VERSION "1"

NS_ :

BS_:

BU_: BMS ECU

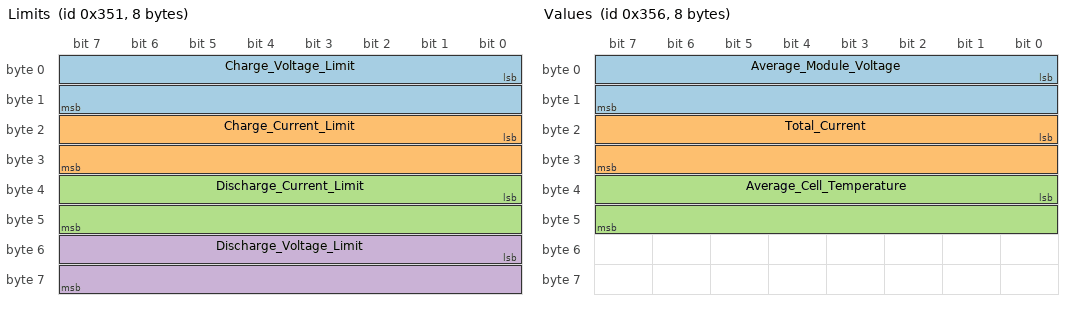
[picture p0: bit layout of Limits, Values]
BO_ 849 Limits: 8 BMS
 SG_ Charge_Voltage_Limit : 0|16@1+ (0.1,0) [0|65.535] "V"  ECU
 SG_ Charge_Current_Limit  : 16|16@1- (0.1,0) [-3276.8|3276.7] "A"  ECU
 SG_ Discharge_Current_Limit  : 32|16@1- (0.1,0) [-3276.8|3276.7] "A"  ECU
 SG_ Discharge_Voltage_Limit : 48|16@1+ (0.1,0) [0|65.535] "V"  ECU

BO_ 853 States: 8 BMS
 SG_ SOC : 0|16@1+ (1,0) [0|100] "%"  ECU
 SG_ SOH : 16|16@1+ (1,0) [0|100] "%"  ECU

BO_ 854 Values: 8 BMS
 SG_ Average_Module_Voltage : 0|16@1+ (0.01,0) [0|655.35] "V"  ECU
 SG_ Total_Current : 16|16@1- (0.1,0) [-3276.8|3276.7] "A"  ECU
 SG_ Average_Cell_Temperature : 32|16@1- (0.1,0) [-3276.8|3276.7] "°C"  ECU

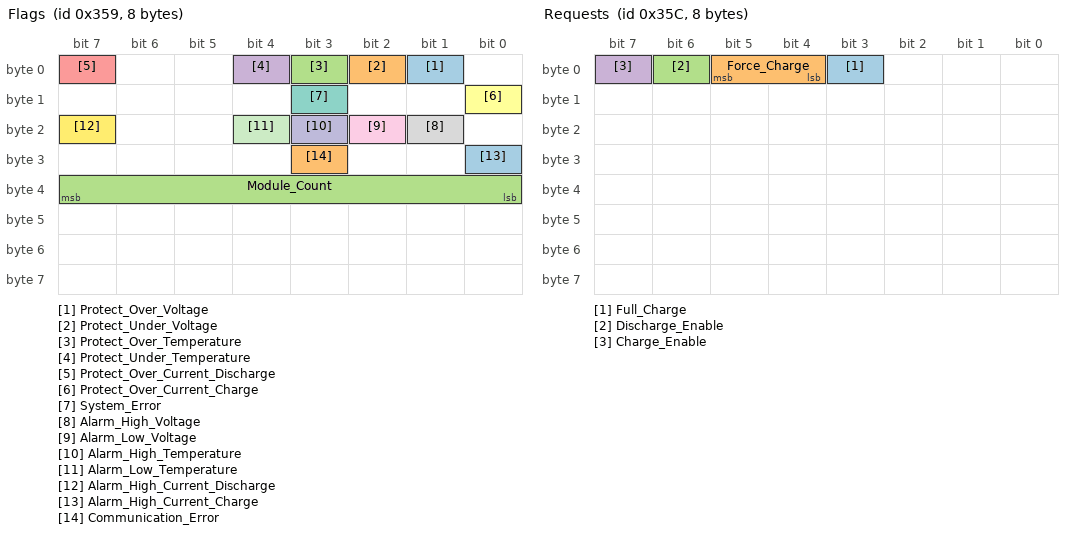
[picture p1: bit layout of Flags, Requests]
BO_ 857 Flags: 8 BMS
 SG_ Protect_Over_Voltage : 1|1@1+ (1,0) [0|1] ""  ECU
 SG_ Protect_Under_Voltage : 2|1@1+ (1,0) [0|1] ""  ECU
 SG_ Protect_Over_Temperature : 3|1@1+ (1,0) [0|1] ""  ECU
 SG_ Protect_Under_Temperature : 4|1@1+ (1,0) [0|1] ""  ECU
 SG_ Protect_Over_Current_Discharge : 7|1@1+ (1,0) [0|1] ""  ECU
 SG_ Protect_Over_Current_Charge : 8|1@1+ (1,0) [0|1] ""  ECU
 SG_ System_Error : 11|1@1+ (1,0) [0|1] ""  ECU
 SG_ Alarm_High_Voltage : 17|1@1+ (1,0) [0|1] ""  ECU
 SG_ Alarm_Low_Voltage : 18|1@1+ (1,0) [0|1] ""  ECU
 SG_ Alarm_High_Temperature : 19|1@1+ (1,0) [0|1] ""  ECU
 SG_ Alarm_Low_Temperature : 20|1@1+ (1,0) [0|1] ""  ECU
 SG_ Alarm_High_Current_Discharge : 23|1@1+ (1,0) [0|1] ""  ECU
 SG_ Alarm_High_Current_Charge : 24|1@1+ (1,0) [0|1] ""  ECU
 SG_ Communication_Error : 27|1@1+ (1,0) [0|1] ""  ECU
 SG_ Module_Count : 32|8@1+ (1,0) [0|65535] ""  ECU

BO_ 860 Requests: 8 BMS
 SG_ Full_Charge : 3|1@1+ (1,0) [0|1] ""  ECU
 SG_ Force_Charge : 4|2@1+ (1,0) [0|1] ""  ECU
 SG_ Discharge_Enable : 6|1@1+ (1,0) [0|1] ""  ECU
 SG_ Charge_Enable : 7|1@1+ (1,0) [0|1] ""  ECU

BO_ 862 Brand: 4 BMS
 SG_ Brand : 0|32@1+ (1,0) [0|128000] ""  ECU

BO_ 863 Firmware: 8 BMS
 SG_ Unknown : 0|64@1+ (1,0) [0|256000] ""  ECU

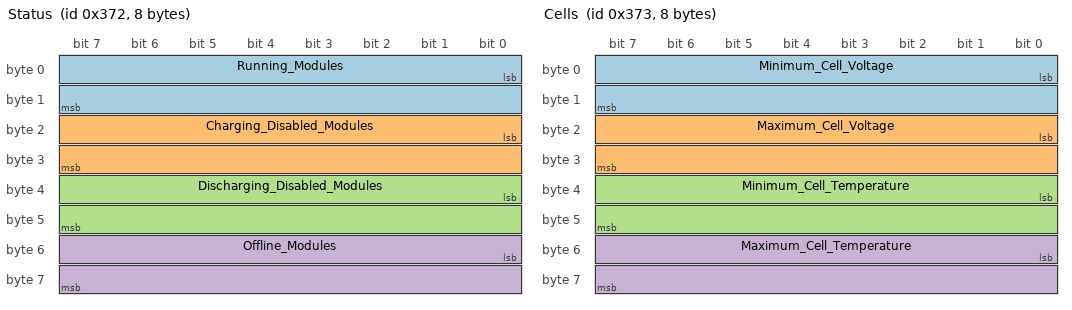
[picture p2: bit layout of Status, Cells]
BO_ 882 Status: 8 BMS
 SG_ Running_Modules : 0|16@1+ (1,0) [0|65535] ""  ECU
 SG_ Charging_Disabled_Modules : 16|16@1+ (1,0) [0|65535] ""  ECU
 SG_ Discharging_Disabled_Modules : 32|16@1+ (1,0) [0|65535] ""  ECU
 SG_ Offline_Modules : 48|16@1+ (1,0) [0|65535] ""  ECU

BO_ 883 Cells: 8 BMS
 SG_ Minimum_Cell_Voltage : 0|16@1+ (0.001,0) [0|65.535] "V"  ECU
 SG_ Maximum_Cell_Voltage : 16|16@1+ (0.001,0) [0|65.535] "V"  ECU
 SG_ Minimum_Cell_Temperature : 32|16@1+ (0.1,0) [0|3276.7] "°C"  ECU
 SG_ Maximum_Cell_Temperature : 48|16@1+ (0.1,0) [0|3276.7] "°C"  ECU

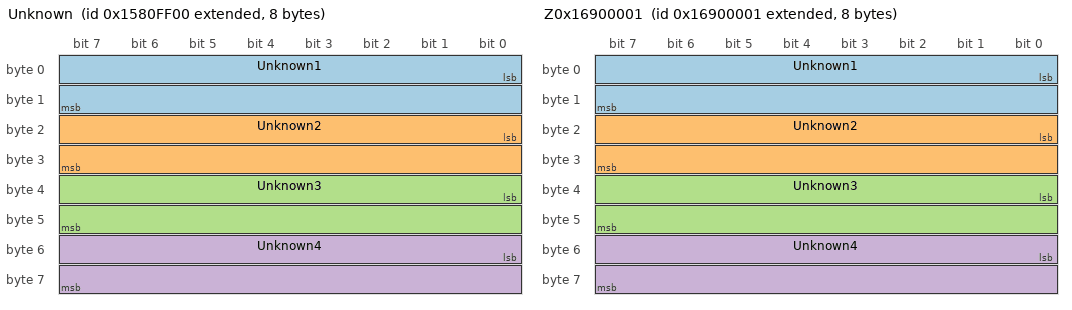
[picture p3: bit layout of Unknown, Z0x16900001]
BO_ 2508259072 Unknown: 8 BMS
 SG_ Unknown1 : 0|16@1+ (1,0) [0|65535] "" ECU
 SG_ Unknown2 : 16|16@1+ (1,0) [0|65535] "" ECU
 SG_ Unknown3 : 32|16@1+ (1,0) [0|65535] "" ECU
 SG_ Unknown4 : 48|16@1+ (1,0) [0|65535] "" ECU

BO_ 2526019585 Z0x16900001: 8 BMS
 SG_ Unknown1 : 0|16@1+ (1,0) [0|65535] "" ECU
 SG_ Unknown2 : 16|16@1+ (1,0) [0|65535] "" ECU
 SG_ Unknown3 : 32|16@1+ (1,0) [0|65535] "" ECU
 SG_ Unknown4 : 48|16@1+ (1,0) [0|65535] "" ECU

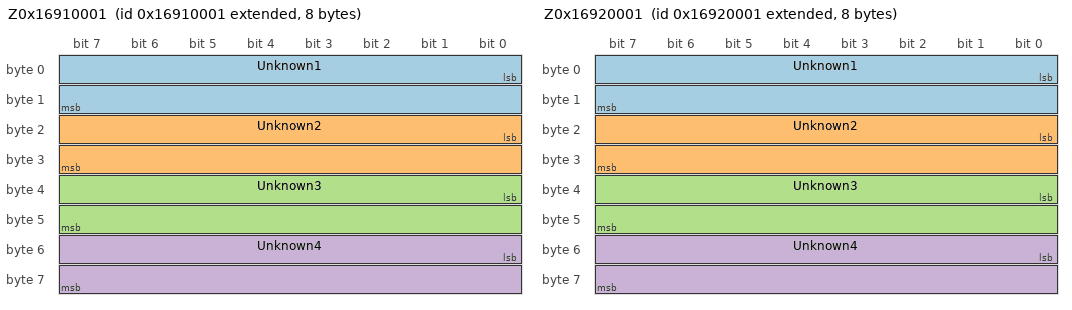
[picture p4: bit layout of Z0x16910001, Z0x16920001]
BO_ 2526085121 Z0x16910001: 8 BMS
 SG_ Unknown1 : 0|16@1+ (1,0) [0|65535] "" ECU
 SG_ Unknown2 : 16|16@1+ (1,0) [0|65535] "" ECU
 SG_ Unknown3 : 32|16@1+ (1,0) [0|65535] "" ECU
 SG_ Unknown4 : 48|16@1+ (1,0) [0|65535] "" ECU

BO_ 2526150657 Z0x16920001: 8 BMS
 SG_ Unknown1 : 0|16@1+ (1,0) [0|65535] "" ECU
 SG_ Unknown2 : 16|16@1+ (1,0) [0|65535] "" ECU
 SG_ Unknown3 : 32|16@1+ (1,0) [0|65535] "" ECU
 SG_ Unknown4 : 48|16@1+ (1,0) [0|65535] "" ECU

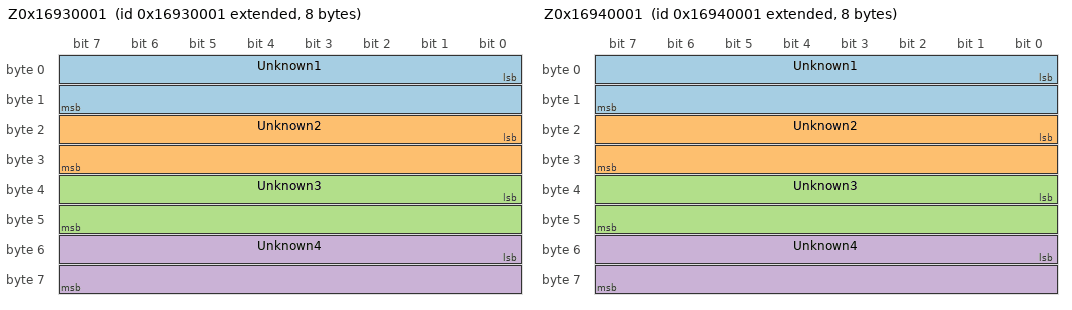
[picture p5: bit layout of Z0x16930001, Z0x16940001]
BO_ 2526216193 Z0x16930001: 8 BMS
 SG_ Unknown1 : 0|16@1+ (1,0) [0|65535] "" ECU
 SG_ Unknown2 : 16|16@1+ (1,0) [0|65535] "" ECU
 SG_ Unknown3 : 32|16@1+ (1,0) [0|65535] "" ECU
 SG_ Unknown4 : 48|16@1+ (1,0) [0|65535] "" ECU

BO_ 2526281729 Z0x16940001: 8 BMS
 SG_ Unknown1 : 0|16@1+ (1,0) [0|65535] "" ECU
 SG_ Unknown2 : 16|16@1+ (1,0) [0|65535] "" ECU
 SG_ Unknown3 : 32|16@1+ (1,0) [0|65535] "" ECU
 SG_ Unknown4 : 48|16@1+ (1,0) [0|65535] "" ECU

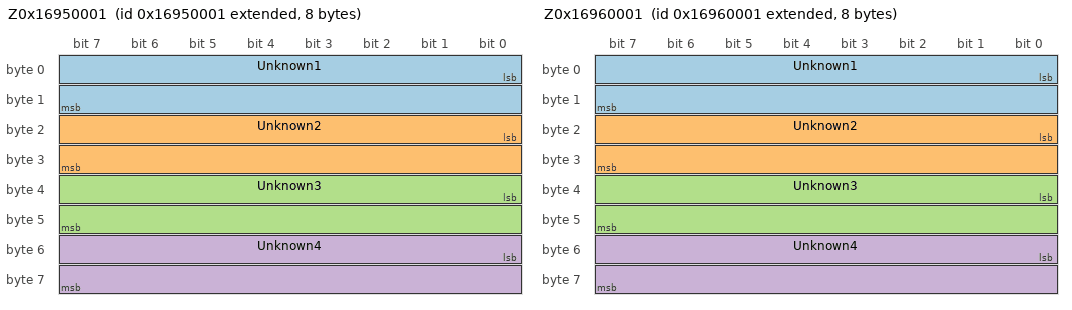
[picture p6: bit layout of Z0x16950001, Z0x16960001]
BO_ 2526347265 Z0x16950001: 8 BMS
 SG_ Unknown1 : 0|16@1+ (1,0) [0|65535] "" ECU
 SG_ Unknown2 : 16|16@1+ (1,0) [0|65535] "" ECU
 SG_ Unknown3 : 32|16@1+ (1,0) [0|65535] "" ECU
 SG_ Unknown4 : 48|16@1+ (1,0) [0|65535] "" ECU

BO_ 2526412801 Z0x16960001: 8 BMS
 SG_ Unknown1 : 0|16@1+ (1,0) [0|65535] "" ECU
 SG_ Unknown2 : 16|16@1+ (1,0) [0|65535] "" ECU
 SG_ Unknown3 : 32|16@1+ (1,0) [0|65535] "" ECU
 SG_ Unknown4 : 48|16@1+ (1,0) [0|65535] "" ECU

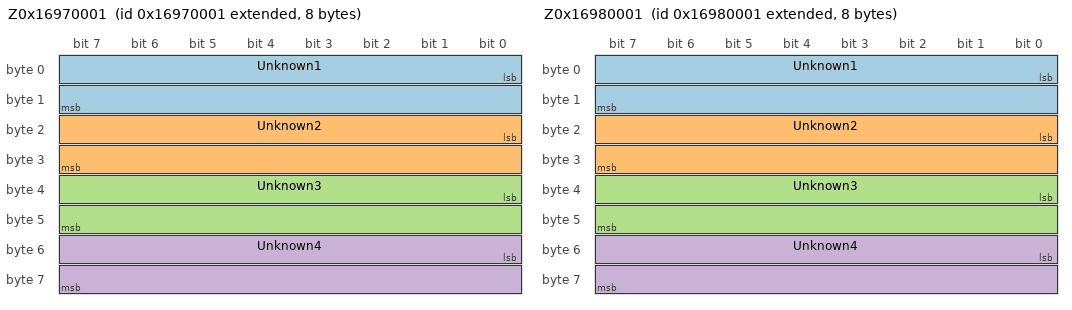
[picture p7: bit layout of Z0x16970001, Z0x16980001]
BO_ 2526478337 Z0x16970001: 8 BMS
 SG_ Unknown1 : 0|16@1+ (1,0) [0|65535] "" ECU
 SG_ Unknown2 : 16|16@1+ (1,0) [0|65535] "" ECU
 SG_ Unknown3 : 32|16@1+ (1,0) [0|65535] "" ECU
 SG_ Unknown4 : 48|16@1+ (1,0) [0|65535] "" ECU

BO_ 2526543873 Z0x16980001: 8 BMS
 SG_ Unknown1 : 0|16@1+ (1,0) [0|65535] "" ECU
 SG_ Unknown2 : 16|16@1+ (1,0) [0|65535] "" ECU
 SG_ Unknown3 : 32|16@1+ (1,0) [0|65535] "" ECU
 SG_ Unknown4 : 48|16@1+ (1,0) [0|65535] "" ECU

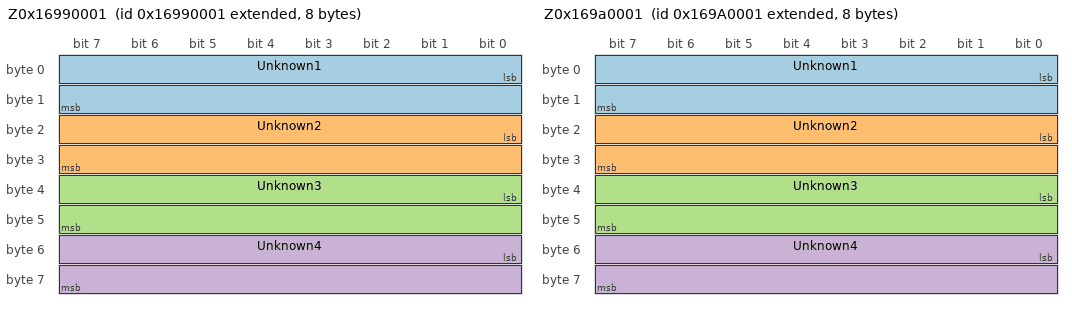
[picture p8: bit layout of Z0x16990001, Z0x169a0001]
BO_ 2526609409 Z0x16990001: 8 BMS
 SG_ Unknown1 : 0|16@1+ (1,0) [0|65535] "" ECU
 SG_ Unknown2 : 16|16@1+ (1,0) [0|65535] "" ECU
 SG_ Unknown3 : 32|16@1+ (1,0) [0|65535] "" ECU
 SG_ Unknown4 : 48|16@1+ (1,0) [0|65535] "" ECU

BO_ 2526674945 Z0x169a0001: 8 BMS
 SG_ Unknown1 : 0|16@1+ (1,0) [0|65535] "" ECU
 SG_ Unknown2 : 16|16@1+ (1,0) [0|65535] "" ECU
 SG_ Unknown3 : 32|16@1+ (1,0) [0|65535] "" ECU
 SG_ Unknown4 : 48|16@1+ (1,0) [0|65535] "" ECU

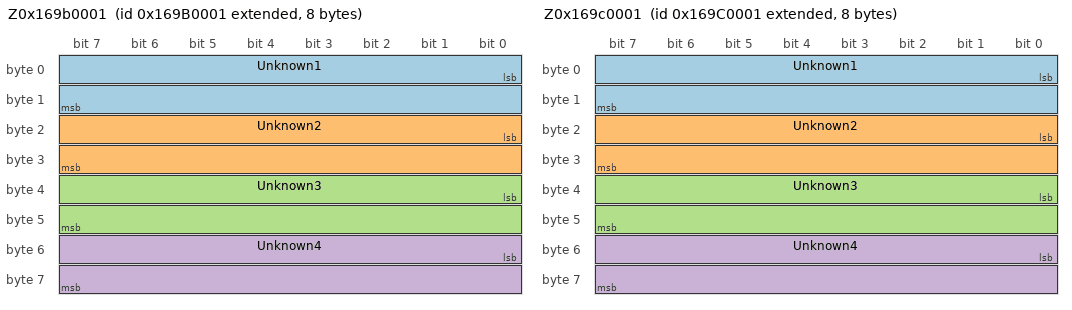
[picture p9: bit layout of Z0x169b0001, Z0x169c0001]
BO_ 2526740481 Z0x169b0001: 8 BMS
 SG_ Unknown1 : 0|16@1+ (1,0) [0|65535] "" ECU
 SG_ Unknown2 : 16|16@1+ (1,0) [0|65535] "" ECU
 SG_ Unknown3 : 32|16@1+ (1,0) [0|65535] "" ECU
 SG_ Unknown4 : 48|16@1+ (1,0) [0|65535] "" ECU

BO_ 2526806017 Z0x169c0001: 8 BMS
 SG_ Unknown1 : 0|16@1+ (1,0) [0|65535] "" ECU
 SG_ Unknown2 : 16|16@1+ (1,0) [0|65535] "" ECU
 SG_ Unknown3 : 32|16@1+ (1,0) [0|65535] "" ECU
 SG_ Unknown4 : 48|16@1+ (1,0) [0|65535] "" ECU

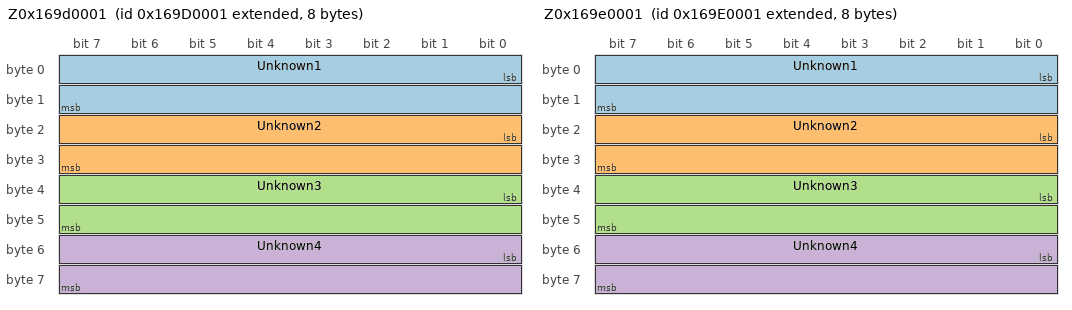
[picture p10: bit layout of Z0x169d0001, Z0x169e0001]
BO_ 2526871553 Z0x169d0001: 8 BMS
 SG_ Unknown1 : 0|16@1+ (1,0) [0|65535] "" ECU
 SG_ Unknown2 : 16|16@1+ (1,0) [0|65535] "" ECU
 SG_ Unknown3 : 32|16@1+ (1,0) [0|65535] "" ECU
 SG_ Unknown4 : 48|16@1+ (1,0) [0|65535] "" ECU

BO_ 2526937089 Z0x169e0001: 8 BMS
 SG_ Unknown1 : 0|16@1+ (1,0) [0|65535] "" ECU
 SG_ Unknown2 : 16|16@1+ (1,0) [0|65535] "" ECU
 SG_ Unknown3 : 32|16@1+ (1,0) [0|65535] "" ECU
 SG_ Unknown4 : 48|16@1+ (1,0) [0|65535] "" ECU

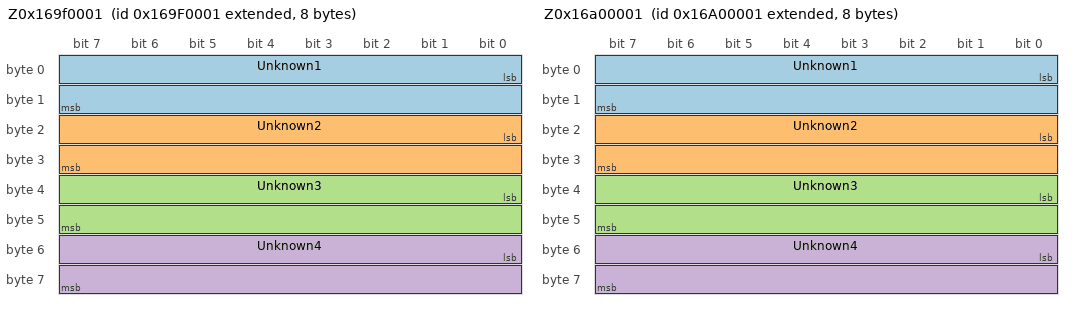
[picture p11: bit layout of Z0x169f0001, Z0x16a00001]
BO_ 2527002625 Z0x169f0001: 8 BMS
 SG_ Unknown1 : 0|16@1+ (1,0) [0|65535] "" ECU
 SG_ Unknown2 : 16|16@1+ (1,0) [0|65535] "" ECU
 SG_ Unknown3 : 32|16@1+ (1,0) [0|65535] "" ECU
 SG_ Unknown4 : 48|16@1+ (1,0) [0|65535] "" ECU

BO_ 2527068161 Z0x16a00001: 8 BMS
 SG_ Unknown1 : 0|16@1+ (1,0) [0|65535] "" ECU
 SG_ Unknown2 : 16|16@1+ (1,0) [0|65535] "" ECU
 SG_ Unknown3 : 32|16@1+ (1,0) [0|65535] "" ECU
 SG_ Unknown4 : 48|16@1+ (1,0) [0|65535] "" ECU

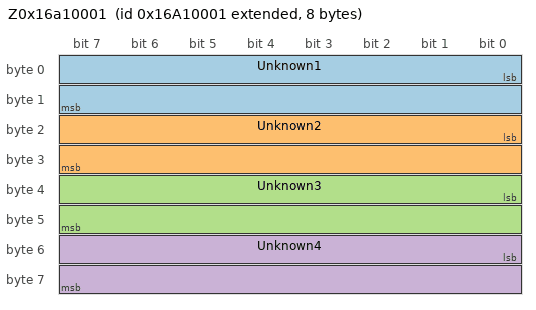
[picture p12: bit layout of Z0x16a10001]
BO_ 2527133697 Z0x16a10001: 8 BMS
 SG_ Unknown1 : 0|16@1+ (1,0) [0|65535] "" ECU
 SG_ Unknown2 : 16|16@1+ (1,0) [0|65535] "" ECU
 SG_ Unknown3 : 32|16@1+ (1,0) [0|65535] "" ECU
 SG_ Unknown4 : 48|16@1+ (1,0) [0|65535] "" ECU
